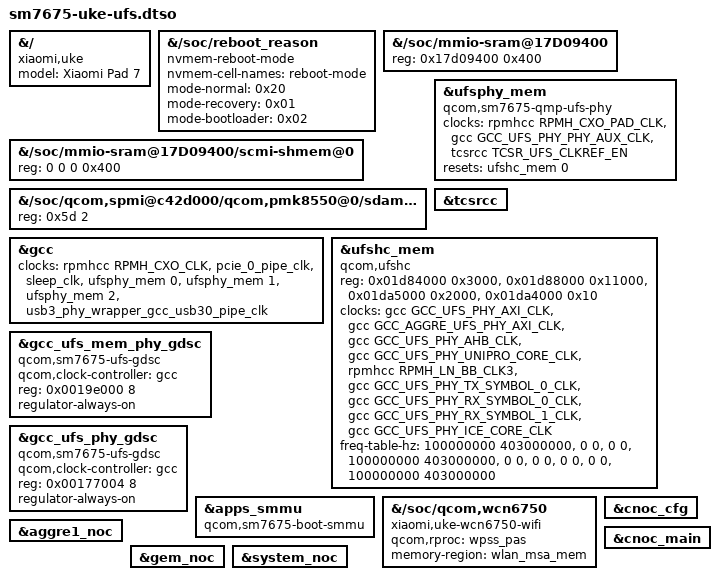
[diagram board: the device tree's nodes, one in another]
// SPDX-License-Identifier: GPL-2.0-only OR BSD-2-Clause
/*
 * Development overlay for an inspected, matching Uke stock DT graph.
 * OEM DT 94c84aeb9e517dbde546fc732033c184094c8e57 (Cliffs/Uke).
 * This is not an Android DTBO image and never supplies RAM or selects a DTB.
 * Requires the UFS PHY, NoC, scoped SMMU/GDSC and RPMh snapshot fixes.
 * PHY clocks use mainline IDs; GCC parents must use this PHY's clock provider.
 * ICE uses the native host-owned path and the exact contiguous OEM windows.
 * MCQ retains its separate OEM operation/status windows and native IRQ path.
 */
/dts-v1/;
/plugin/;

#include <dt-bindings/clock/qcom,gcc-cliffs.h>
#include <dt-bindings/clock/qcom,rpmh.h>
#include <dt-bindings/clock/qcom,tcsrcc-pineapple.h>
#include "sm7675-uke-adreno732.dtsi"

/* Stock overlay root metadata does not itself overlay the runtime root.
 * Express the inspected Uke board identity as a real root-target fragment.
 * Keep OEM selectors, RAM, reservations and unit-specific data untouched.
 */
&{/} {
	model = "Xiaomi Pad 7";
	compatible = "xiaomi,uke", "qcom,sm7675", "qcom,cliffs";
};

/* OEM qcom-reboot-reason uses this PMK8550 cell and these exact mode values.
 * Use the upstream backend without copying the vendor panic notifier.
 */
&{/soc/reboot_reason} {
	compatible = "nvmem-reboot-mode";
	nvmem-cell-names = "reboot-mode";
	mode-normal = <0x20>;
	mode-recovery = <0x01>;
	mode-bootloader = <0x02>;
};

/* Parent /soc uses one address and size cell; child SRAM offsets use two. */
&{/soc/mmio-sram@17D09400} {
	reg = <0x17d09400 0x400>;
	ranges = <0 0 0x17d09400 0 0x400>;
};

&{/soc/mmio-sram@17D09400/scmi-shmem@0} {
	reg = <0 0 0 0x400>;
};

/* OEM NVMEM expands this five-bit field at bit five into two bytes. */
&{/soc/qcom,spmi@c42d000/qcom,pmk8550@0/sdam@7000/smb1510_present@5d} {
	reg = <0x5d 2>;
};

&ufsphy_mem {
	compatible = "qcom,sm7675-qmp-ufs-phy";
	clocks = <&rpmhcc RPMH_CXO_PAD_CLK>,
		 <&gcc GCC_UFS_PHY_PHY_AUX_CLK>,
		 <&tcsrcc TCSR_UFS_CLKREF_EN>;
	clock-names = "ref", "ref_aux", "qref";
	resets = <&ufshc_mem 0>;
	reset-names = "ufsphy";
	#clock-cells = <1>;
	#phy-cells = <0>;
	status = "okay";
};

&gcc {
	clocks = <&rpmhcc RPMH_CXO_CLK>, <&pcie_0_pipe_clk>, <&sleep_clk>,
		 <&ufsphy_mem 0>, <&ufsphy_mem 1>, <&ufsphy_mem 2>,
		 <&usb3_phy_wrapper_gcc_usb30_pipe_clk>;
};

&tcsrcc {
	status = "okay";
};

&ufshc_mem {
	/* Generic upstream host reads the actual controller version. */
	compatible = "qcom,ufshc";
	reg = <0x01d84000 0x3000>, <0x01d88000 0x11000>,
	      <0x01da5000 0x2000>, <0x01da4000 0x10>;
	reg-names = "std", "ice", "mcq_sqd", "mcq_vs";
	clocks = <&gcc GCC_UFS_PHY_AXI_CLK>,
		 <&gcc GCC_AGGRE_UFS_PHY_AXI_CLK>,
		 <&gcc GCC_UFS_PHY_AHB_CLK>,
		 <&gcc GCC_UFS_PHY_UNIPRO_CORE_CLK>,
		 <&rpmhcc RPMH_LN_BB_CLK3>,
		 <&gcc GCC_UFS_PHY_TX_SYMBOL_0_CLK>,
		 <&gcc GCC_UFS_PHY_RX_SYMBOL_0_CLK>,
		 <&gcc GCC_UFS_PHY_RX_SYMBOL_1_CLK>,
		 <&gcc GCC_UFS_PHY_ICE_CORE_CLK>;
	clock-names = "core_clk", "bus_aggr_clk", "iface_clk",
		      "core_clk_unipro", "ref_clk", "tx_lane0_sync_clk",
		      "rx_lane0_sync_clk", "rx_lane1_sync_clk", "ice_core_clk";
	freq-table-hz = <100000000 403000000>, <0 0>, <0 0>,
			<100000000 403000000>, <0 0>, <0 0>, <0 0>, <0 0>,
			<100000000 403000000>;
	status = "okay";
};

&gcc_ufs_mem_phy_gdsc {
	compatible = "qcom,sm7675-ufs-gdsc";
	qcom,clock-controller = <&gcc>;
	reg = <0x0019e000 8>;
	regulator-always-on;
	status = "okay";
};

&gcc_ufs_phy_gdsc {
	compatible = "qcom,sm7675-ufs-gdsc";
	qcom,clock-controller = <&gcc>;
	reg = <0x00177004 8>;
	regulator-always-on;
	status = "okay";
};

&apps_smmu {
	/* Extended DMA admission uses the primary match. The register/handoff
	 * protocol retains the original core driver's USB-compatible fallback.
	 */
	compatible = "qcom,sm7675-boot-smmu", "qcom,sm7675-usb-smmu";
};

&{/soc/qcom,wcn6750} {
	compatible = "xiaomi,uke-wcn6750-wifi", "qcom,wcn6750-wifi";
	qcom,rproc = <&wpss_pas>;
	memory-region = <&wlan_msa_mem>;
	status = "okay";
};

&aggre1_noc { status = "okay"; };
&cnoc_cfg { status = "okay"; };
&cnoc_main { status = "okay"; };
&gem_noc { status = "okay"; };
&system_noc { status = "okay"; };
